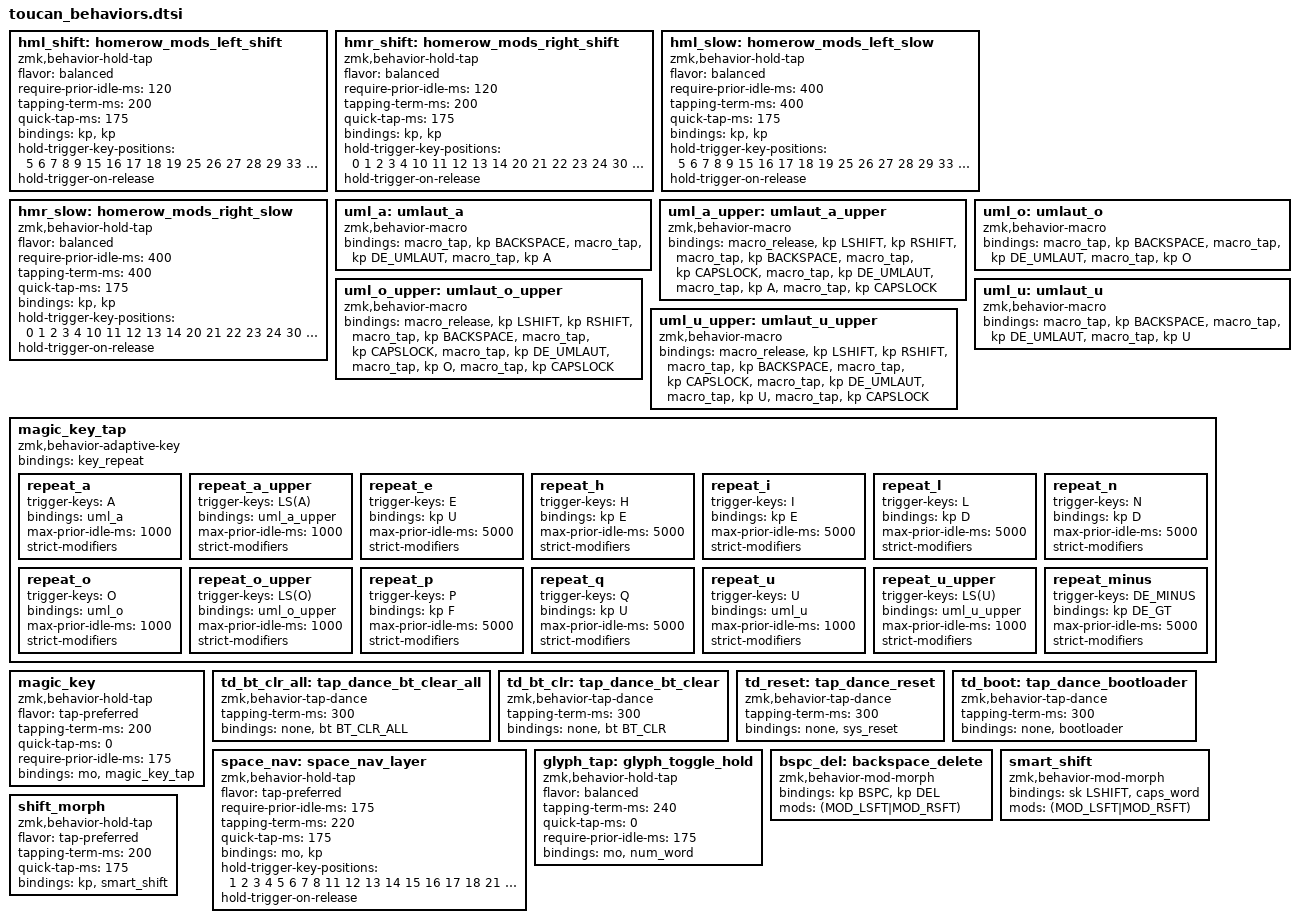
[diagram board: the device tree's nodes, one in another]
// =============================================================================
// Custom Behaviors for Toucan
// =============================================================================
// Layer reference:
//   0 = Gallium (default)   1 = Glyph   2 = Helm   3 = Bridge
//
// Timing Summary:
//   Home row mods — Shift (hml_shift/hmr_shift):          200ms tap, 175ms quick-tap, 120ms prior-idle
//   Home row mods — Ctrl/Alt/Super (hml_slow/hmr_slow):   400ms tap, 175ms quick-tap, 400ms prior-idle
//   Space/Nav (space_nav):         220ms tap, 175ms quick-tap, 175ms prior-idle
//   Magic Key (magic_key):         200ms tap, 0ms quick-tap (tap-preferred)
//   Glyph (glyph_tap):             240ms tap, 0ms quick-tap (balanced)
//   Tap-dances (safety wrappers):  300ms double-tap window
//   Combos:                        50ms timeout, 300-400ms prior-idle
//
// =============================================================================

// -----------------------------------------------------------------------------
// HOME ROW MODS — SHIFT (aggressive)
// -----------------------------------------------------------------------------
// Faster activation for Shift — used constantly during normal typing.
// Timing: 200ms tapping term, 175ms quick-tap, 120ms prior-idle guard.

// Left-hand Shift HRM
hml_shift: homerow_mods_left_shift {
    compatible = "zmk,behavior-hold-tap";
    #binding-cells = <2>;
    flavor = "balanced";
    require-prior-idle-ms = <120>;
    tapping-term-ms = <200>;
    quick-tap-ms = <175>;
    bindings = <&kp>, <&kp>;
    hold-trigger-key-positions = <5 6 7 8 9 15 16 17 18 19 25 26 27 28 29 33 34 35>;
    hold-trigger-on-release;
};

// Right-hand Shift HRM
hmr_shift: homerow_mods_right_shift {
    compatible = "zmk,behavior-hold-tap";
    #binding-cells = <2>;
    flavor = "balanced";
    require-prior-idle-ms = <120>;
    tapping-term-ms = <200>;
    quick-tap-ms = <175>;
    bindings = <&kp>, <&kp>;
    hold-trigger-key-positions = <0 1 2 3 4 10 11 12 13 14 20 21 22 23 24 30 31 32>;
    hold-trigger-on-release;
};

// -----------------------------------------------------------------------------
// HOME ROW MODS — CTRL / ALT / SUPER (conservative)
// -----------------------------------------------------------------------------
// Slow, deliberate activation — these modifiers are used rarely and always
// intentionally. Long tapping-term and long prior-idle prevent any accidental
// triggering during normal typing.
// Timing: 400ms tapping term, 175ms quick-tap, 400ms prior-idle guard.

// Left-hand Ctrl/Alt/Super HRM
hml_slow: homerow_mods_left_slow {
    compatible = "zmk,behavior-hold-tap";
    #binding-cells = <2>;
    flavor = "balanced";
    require-prior-idle-ms = <400>;
    tapping-term-ms = <400>;
    quick-tap-ms = <175>;
    bindings = <&kp>, <&kp>;
    hold-trigger-key-positions = <5 6 7 8 9 15 16 17 18 19 25 26 27 28 29 33 34 35>;
    hold-trigger-on-release;
};

// Right-hand Ctrl/Alt/Super HRM
hmr_slow: homerow_mods_right_slow {
    compatible = "zmk,behavior-hold-tap";
    #binding-cells = <2>;
    flavor = "balanced";
    require-prior-idle-ms = <400>;
    tapping-term-ms = <400>;
    quick-tap-ms = <175>;
    bindings = <&kp>, <&kp>;
    hold-trigger-key-positions = <0 1 2 3 4 10 11 12 13 14 20 21 22 23 24 30 31 32>;
    hold-trigger-on-release;
};

// -----------------------------------------------------------------------------
// UMLAUT MACROS
// -----------------------------------------------------------------------------
// Implementation for German umlauts (ä, ö, ü) using dead key composition.
// Method: backspace + DE_UMLAUT dead key + base vowel
// The OS composes these into the final umlaut character.
//
// Lowercase umlauts (a/o/u → ä/ö/ü):
//   - Release any active shift
//   - Backspace to remove the triggering letter
//   - Type: dead umlaut + base vowel
//
// Uppercase umlauts (A/O/U → Ä/Ö/Ü):
//   - Release any active shift
//   - Backspace to remove the triggering letter
//   - Temporarily enable CAPSLOCK
//   - Type: dead umlaut + base vowel
//   - Disable CAPSLOCK
//
// Note: These are triggered by the magic_key adaptive behavior after typing a/A/o/O/u/U
// -----------------------------------------------------------------------------

// ä — backspace + dead umlaut + a
uml_a: umlaut_a {
    compatible = "zmk,behavior-macro";
    #binding-cells = <0>;
    bindings
        = <&macro_tap &kp BACKSPACE>
        , <&macro_tap &kp DE_UMLAUT>
        , <&macro_tap &kp A>
        ;
};

// Ä
uml_a_upper: umlaut_a_upper {
    compatible = "zmk,behavior-macro";
    #binding-cells = <0>;
    bindings
        = <&macro_release &kp LSHIFT &kp RSHIFT>
        , <&macro_tap &kp BACKSPACE>
        , <&macro_tap &kp CAPSLOCK>
        , <&macro_tap &kp DE_UMLAUT>
        , <&macro_tap &kp A>
        , <&macro_tap &kp CAPSLOCK>
        ;
};

// ö — backspace + dead umlaut + o
uml_o: umlaut_o {
    compatible = "zmk,behavior-macro";
    #binding-cells = <0>;
    bindings
        = <&macro_tap &kp BACKSPACE>
        , <&macro_tap &kp DE_UMLAUT>
        , <&macro_tap &kp O>
        ;
};

// Ö
uml_o_upper: umlaut_o_upper {
    compatible = "zmk,behavior-macro";
    #binding-cells = <0>;
    bindings
        = <&macro_release &kp LSHIFT &kp RSHIFT>
        , <&macro_tap &kp BACKSPACE>
        , <&macro_tap &kp CAPSLOCK>
        , <&macro_tap &kp DE_UMLAUT>
        , <&macro_tap &kp O>
        , <&macro_tap &kp CAPSLOCK>
        ;
};

// ü — backspace + dead umlaut + u
uml_u: umlaut_u {
    compatible = "zmk,behavior-macro";
    #binding-cells = <0>;
    bindings
        = <&macro_tap &kp BACKSPACE>
        , <&macro_tap &kp DE_UMLAUT>
        , <&macro_tap &kp U>
        ;
};

// Ü
uml_u_upper: umlaut_u_upper {
    compatible = "zmk,behavior-macro";
    #binding-cells = <0>;
    bindings
        = <&macro_release &kp LSHIFT &kp RSHIFT>
        , <&macro_tap &kp BACKSPACE>
        , <&macro_tap &kp CAPSLOCK>
        , <&macro_tap &kp DE_UMLAUT>
        , <&macro_tap &kp U>
        , <&macro_tap &kp CAPSLOCK>
        ;
};

// -----------------------------------------------------------------------------
// MAGIC KEY SYSTEM
// -----------------------------------------------------------------------------
// The Magic Key provides intelligent repeat and context-aware substitutions.
//
// Adaptive substitutions (within timeout window):
//   Letter bigrams: C→H E→U H→E I→E L→D N→D P→F Q→U
//   Special pairs:  -→>
//   Umlauts (1s):   a→ä A→Ä o→ö O→Ö u→ü U→Ü
//   Default:        key_repeat (any other key)
//
// Bigram rationale (häufig in DE + mühsam auf Gallium):
//   C→H «ch»: häufig (auch/ich/noch), Alternation L↔R — hohe Frequenz rechtfertigt Magic
//   E→U «eu»: SFB (Ringfinger rechts x2), «heute/neu/Euro»
//   H→E «he»: rückwärts skip-finger rechts, «heben/hell/her»
//   I→E «ie»: rückwärts Roll (Kleinfinger→Ringfinger rechts), «die/wie/nie/viel»
//   L→D «ld»: rückwärts Roll gleiche Reihe links, «Wald/Geld/wild»
//   N→D «nd»: rückwärts (home→top) links, «und/Kind/Hand»
//   P→F «pf»: SFB (Zeigefinger rechts x2), «Pferd/Kopf/Pfanne»
//   Q→U «qu»: Q kommt praktisch nie ohne U vor
//
// Timeout windows:
//   - Umlauts: 1000ms (1 second) - must be typed quickly after vowel
//   - Letter substitutions: 5000ms (5 seconds) - longer window for natural typing
// -----------------------------------------------------------------------------

magic_key_tap: magic_key_tap {
    compatible = "zmk,behavior-adaptive-key";
    #binding-cells = <0>;
    bindings = <&key_repeat>;

    // a → ä
    repeat_a {
        trigger-keys = <A>;
        bindings = <&uml_a>;
        max-prior-idle-ms = <1000>;
        strict-modifiers;
    };

    // A → Ä
    repeat_a_upper {
        trigger-keys = <LS(A)>;
        bindings = <&uml_a_upper>;
        max-prior-idle-ms = <1000>;
        strict-modifiers;
    };

    // E → output U (bigram «eu»: SFB Ringfinger rechts, «heute/neu/Euro»)
    repeat_e {
        trigger-keys = <E>;
        bindings = <&kp U>;
        max-prior-idle-ms = <5000>;
        strict-modifiers;
    };

    // H → output E (bigram «he»: rückwärts skip-finger rechts, «heben/hell/her»)
    repeat_h {
        trigger-keys = <H>;
        bindings = <&kp E>;
        max-prior-idle-ms = <5000>;
        strict-modifiers;
    };

    // I → output E (bigram «ie»: rückwärts Roll Kleinfinger→Ringfinger rechts, «die/wie/nie»)
    repeat_i {
        trigger-keys = <I>;
        bindings = <&kp E>;
        max-prior-idle-ms = <5000>;
        strict-modifiers;
    };

    // L → output D (bigram «ld»: rückwärts Roll gleiche Reihe links, «Wald/Geld/wild»)
    repeat_l {
        trigger-keys = <L>;
        bindings = <&kp D>;
        max-prior-idle-ms = <5000>;
        strict-modifiers;
    };

    // N → output D (bigram «nd»: rückwärts home→top links, «und/Kind/Hand»)
    repeat_n {
        trigger-keys = <N>;
        bindings = <&kp D>;
        max-prior-idle-ms = <5000>;
        strict-modifiers;
    };

    // o → ö
    repeat_o {
        trigger-keys = <O>;
        bindings = <&uml_o>;
        max-prior-idle-ms = <1000>;
        strict-modifiers;
    };

    // O → Ö
    repeat_o_upper {
        trigger-keys = <LS(O)>;
        bindings = <&uml_o_upper>;
        max-prior-idle-ms = <1000>;
        strict-modifiers;
    };

    // P → output F (bigram «pf»: SFB Zeigefinger rechts, «Pferd/Kopf/Pfanne»)
    repeat_p {
        trigger-keys = <P>;
        bindings = <&kp F>;
        max-prior-idle-ms = <5000>;
        strict-modifiers;
    };

    // Q → output U (bigram «qu»: Q kommt praktisch nie ohne U vor)
    repeat_q {
        trigger-keys = <Q>;
        bindings = <&kp U>;
        max-prior-idle-ms = <5000>;
        strict-modifiers;
    };

    // u → ü
    repeat_u {
        trigger-keys = <U>;
        bindings = <&uml_u>;
        max-prior-idle-ms = <1000>;
        strict-modifiers;
    };

    // U → Ü
    repeat_u_upper {
        trigger-keys = <LS(U)>;
        bindings = <&uml_u_upper>;
        max-prior-idle-ms = <1000>;
        strict-modifiers;
    };

    // - → output > (arrow: ->)
    repeat_minus {
        trigger-keys = <DE_MINUS>;
        bindings = <&kp DE_GT>;
        max-prior-idle-ms = <5000>;
        strict-modifiers;
    };

};

// The Magic Key on the default layer thumb cluster.
// Hold = momentary layer activation (&mo), Tap = magic_key_tap (adaptive repeat/substitution).
// Timing: 200ms tapping term (tap-preferred), 0ms quick-tap.
magic_key: magic_key {
    compatible = "zmk,behavior-hold-tap";
    #binding-cells = <2>;
    flavor = "tap-preferred";
    tapping-term-ms = <200>;
    quick-tap-ms = <0>;
    require-prior-idle-ms = <175>;
    bindings = <&mo>, <&magic_key_tap>;
};

// -----------------------------------------------------------------------------
// TAP-DANCE SAFETY WRAPPERS (dangerous / destructive actions)
// Single tap = nothing. Double tap = action.
// Prevents accidental triggering of destructive system functions.
// -----------------------------------------------------------------------------

// Double-tap to clear ALL Bluetooth profiles. Single tap is a no-op.
td_bt_clr_all: tap_dance_bt_clear_all {
    compatible = "zmk,behavior-tap-dance";
    #binding-cells = <0>;
    tapping-term-ms = <300>;
    bindings = <&none>, <&bt BT_CLR_ALL>;
};

// Double-tap to clear the CURRENT Bluetooth profile. Single tap is a no-op.
td_bt_clr: tap_dance_bt_clear {
    compatible = "zmk,behavior-tap-dance";
    #binding-cells = <0>;
    tapping-term-ms = <300>;
    bindings = <&none>, <&bt BT_CLR>;
};

// Double-tap to trigger a system reset. Single tap is a no-op.
td_reset: tap_dance_reset {
    compatible = "zmk,behavior-tap-dance";
    #binding-cells = <0>;
    tapping-term-ms = <300>;
    bindings = <&none>, <&sys_reset>;
};

// Double-tap to enter the bootloader. Single tap is a no-op.
td_boot: tap_dance_bootloader {
    compatible = "zmk,behavior-tap-dance";
    #binding-cells = <0>;
    tapping-term-ms = <300>;
    bindings = <&none>, <&bootloader>;
};

// -----------------------------------------------------------------------------
// NAV LAYER SPECIAL BEHAVIOURS
// -----------------------------------------------------------------------------
// The Space/Nav thumb key on the default layer.
// Hold = momentary Bridge layer (&mo), Tap = plain space (&kp DE_SPACE).
// Cross-hand hold-trigger positions exclude dangerous reset/bootloader key positions
// (positions 0, 9, 10, 19, 20, 29 are excluded for safety).
// Timing: 220ms tapping term, 175ms quick-tap, 175ms prior-idle guard.
//
// Hold-trigger positions (excludes corner keys with dangerous actions):
//    —   ✓   ✓   ✓   ✓  |  ✓   ✓   ✓   ✓   —      positions 1-8 (not 0,9)
//    —   ✓   ✓   ✓   ✓  |  ✓   ✓   ✓   ✓   —      positions 11-18 (not 10,19)
//    —   ✓   ✓   ✓   ✓  |  ✓   ✓   ✓   ✓   —      positions 21-28 (not 20,29)
//                ✓   ✓   ✓   |  ✓   ✓   ✓           positions 30-35
space_nav: space_nav_layer {
    compatible = "zmk,behavior-hold-tap";
    #binding-cells = <2>;
    flavor = "tap-preferred";
    require-prior-idle-ms = <175>;
    tapping-term-ms = <220>;
    quick-tap-ms = <175>;
    bindings = <&mo>, <&kp>;
    hold-trigger-key-positions = <1 2 3 4 5 6 7 8 11 12 13 14 15 16 17 18 21 22 23 24 25 26 27 28 30 31 32 33 34 35>;
    hold-trigger-on-release;
};

// -----------------------------------------------------------------------------
// GLYPH THUMB KEY
// -----------------------------------------------------------------------------
// The Glyph thumb key on the default layer.
// Hold = momentary Glyph layer (&mo), Tap = num_word (urob's auto-layer:
// activates a number layer that auto-exits when non-number keys are pressed).
// Timing: 240ms tapping term (balanced), 0ms quick-tap.
glyph_tap: glyph_toggle_hold {
    compatible = "zmk,behavior-hold-tap";
    #binding-cells = <2>;
    flavor = "balanced";
    tapping-term-ms = <240>;
    quick-tap-ms = <0>;
    require-prior-idle-ms = <175>;
    bindings = <&mo>, <&num_word>;
};

// -----------------------------------------------------------------------------
// BACKSPACE / DELETE MOD-MORPH
// -----------------------------------------------------------------------------
// Tap = Backspace, Shift+Tap = Delete
bspc_del: backspace_delete {
    compatible = "zmk,behavior-mod-morph";
    #binding-cells = <0>;
    bindings = <&kp BSPC>, <&kp DEL>;
    mods = <(MOD_LSFT|MOD_RSFT)>;
};

// -----------------------------------------------------------------------------
// SMART SHIFT
// -----------------------------------------------------------------------------
// Three-in-one shift key for the left thumb:
//   Tap        = Sticky Shift (&sk LSHIFT) — capitalises the next keypress only
//   Hold       = Regular Shift (&kp LSHIFT) — works like a standard shift key
//   Double-tap = Caps Word — capitalises until a word boundary is reached
//
// Double-tap is implemented as a mod-morph (Shift + tap → Caps Word),
// avoiding tap-dance delays on every single tap.
// -----------------------------------------------------------------------------

// Tap = sticky-shift; when already shifted (from the hold), tap → caps_word.
smart_shift: smart_shift {
    compatible = "zmk,behavior-mod-morph";
    #binding-cells = <0>;
    bindings = <&sk LSHIFT>, <&caps_word>;
    mods = <(MOD_LSFT|MOD_RSFT)>;
};

// Hold = regular shift, Tap = smart_shift (sticky-shift / caps-word).
// Timing: 200ms tapping term, tap-preferred to keep single taps snappy.
shift_morph: shift_morph {
    compatible = "zmk,behavior-hold-tap";
    #binding-cells = <2>;
    flavor = "tap-preferred";
    tapping-term-ms = <200>;
    quick-tap-ms = <175>;
    bindings = <&kp>, <&smart_shift>;
};
